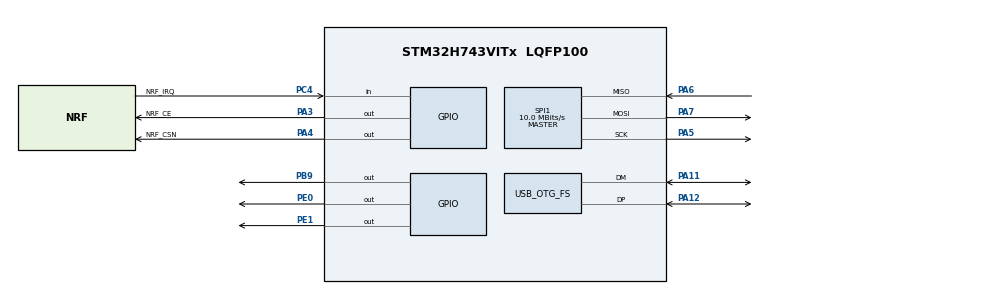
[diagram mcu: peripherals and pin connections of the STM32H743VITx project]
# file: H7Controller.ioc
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FREERTOS.Tasks01=defaultTask,24,128,StartDefaultTask,Default,NULL,Dynamic,NULL,NULL
FREERTOS.configENABLE_FPU=1
FREERTOS.configUSE_PREEMPTION=1
Mcu.Family=STM32H7
Mcu.Name=STM32H743VITx
Mcu.Package=LQFP100
NVIC.OTG_FS_IRQn=true\:5\:0\:false\:false\:true\:true\:false\:true\:true
NVIC.PriorityGroup=NVIC_PRIORITYGROUP_4
NVIC.TIM17_IRQn=true\:15\:0\:false\:false\:true\:false\:false\:true\:true
NVIC.TimeBase=TIM17_IRQn
NVIC.TimeBaseIP=TIM17
PA11.Mode=Device_Only
PA11.Signal=USB_OTG_FS_DM
PA12.Mode=Device_Only
PA12.Signal=USB_OTG_FS_DP
PA13\ (JTMS/SWDIO).Mode=Serial_Wire
PA13\ (JTMS/SWDIO).Signal=DEBUG_JTMS-SWDIO
PA14\ (JTCK/SWCLK).Mode=Serial_Wire
PA14\ (JTCK/SWCLK).Signal=DEBUG_JTCK-SWCLK
PA3.GPIO_Label=NRF_CE
PA3.GPIO_PuPd=GPIO_PULLDOWN
PA3.Signal=GPIO_Output
PA4.GPIO_Label=NRF_CSN
PA4.GPIO_PuPd=GPIO_PULLDOWN
PA4.Signal=GPIO_Output
PA5.Mode=Full_Duplex_Master
PA5.Signal=SPI1_SCK
PA6.Mode=Full_Duplex_Master
PA6.Signal=SPI1_MISO
PA7.Mode=Full_Duplex_Master
PA7.Signal=SPI1_MOSI
PB9.GPIO_PuPd=GPIO_PULLDOWN
PB9.Signal=GPIO_Output
PC4.GPIO_Label=NRF_IRQ
PC4.GPIO_PuPd=GPIO_PULLDOWN
PC4.Signal=GPIO_Input
PE0.GPIO_PuPd=GPIO_PULLDOWN
PE0.Signal=GPIO_Output
PE1.GPIO_PuPd=GPIO_PULLDOWN
PE1.Signal=GPIO_Output
PH0-OSC_IN\ (PH0).Mode=HSE-External-Clock-Source
PH0-OSC_IN\ (PH0).Signal=RCC_OSC_IN
ProjectManager.HeapSize=0x200
ProjectManager.StackSize=0x400
ProjectManager.TargetToolchain=Makefile
RCC.ADCFreq_Value=160000000
RCC.APB1Freq_Value=120000000
RCC.APB2Freq_Value=120000000
RCC.APB3Freq_Value=120000000
RCC.APB4Freq_Value=120000000
RCC.CortexFreq_Value=480000000
RCC.D1PPRE=RCC_APB3_DIV2
RCC.D2PPRE1=RCC_APB1_DIV2
RCC.D2PPRE2=RCC_APB2_DIV2
RCC.D3PPRE=RCC_APB4_DIV2
RCC.DIVM1=5
RCC.DIVM2=5
RCC.DIVM3=5
RCC.DIVN1=192
RCC.DIVN2=192
RCC.DIVN3=192
RCC.DIVP2=6
RCC.HCLKFreq_Value=240000000
RCC.HPRE=RCC_HCLK_DIV2
RCC.PLL2FRACN=0
RCC.PLL3FRACN=0
RCC.PLLFRACN=0
RCC.PLLSourceVirtual=RCC_PLLSOURCE_HSE
RCC.PWR_Regulator_Voltage_Scale=PWR_REGULATOR_VOLTAGE_SCALE0
RCC.ProductRev=revV
RCC.RCC_TIM_PRescaler_Selection=RCC_TIMPRES_DESACTIVATED
RCC.SPI123CLockSelection=RCC_SPI123CLKSOURCE_PLL2
RCC.SYSCLKFreq_VALUE=480000000
RCC.SYSCLKSource=RCC_SYSCLKSOURCE_PLLCLK
RCC.SupplySource=PWR_LDO_SUPPLY
RCC.USBCLockSelection=RCC_USBCLKSOURCE_HSI48
RCC.USBFreq_Value=48000000
SPI1.BaudRatePrescaler=SPI_BAUDRATEPRESCALER_16
SPI1.CalculateBaudRate=10.0 MBits/s
SPI1.DataSize=SPI_DATASIZE_8BIT
SPI1.Direction=SPI_DIRECTION_2LINES
SPI1.Mode=SPI_MODE_MASTER
SPI1.VirtualType=VM_MASTER
USB_DEVICE.APP_RX_DATA_SIZE-CDC_FS=1024
USB_DEVICE.APP_TX_DATA_SIZE-CDC_FS=1024
USB_DEVICE.CLASS_NAME_FS=CDC
USB_DEVICE.VirtualMode-CDC_FS=Cdc
USB_DEVICE.VirtualModeFS=Cdc_FS
USB_OTG_FS.VirtualMode=Device_Only
VP_FREERTOS_VS_CMSIS_V2.Mode=CMSIS_V2
VP_SYS_VS_tim17.Mode=TIM17
VP_USB_DEVICE_VS_USB_DEVICE_CDC_FS.Mode=CDC_FS
board=custom

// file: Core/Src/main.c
/* USER CODE BEGIN Header */
/**
  ******************************************************************************
  * @file           : main.c
  * @brief          : Main program body
  ******************************************************************************
  * @attention
  *
  * Copyright (c) 2023 STMicroelectronics.
  * All rights reserved.
  *
  * This software is licensed under terms that can be found in the LICENSE file
  * in the root directory of this software component.
  * If no LICENSE file comes with this software, it is provided AS-IS.
  *
  ******************************************************************************
  */
/* USER CODE END Header */
#include "main.h"
#include "cmsis_os.h"
#include "spi.h"
#include "usb_device.h"
#include "gpio.h"

/* USER CODE BEGIN Includes */
#include "nrf.h"
#include "Rtcc.h"
/* USER CODE END Includes */

void SystemClock_Config(void);
void MX_FREERTOS_Init(void);

int main(void)
{

  /* MCU Configuration--------------------------------------------------------*/

  /* Reset of all peripherals, Initializes the Flash interface and the Systick. */
  HAL_Init();

  /* Configure the system clock */
  SystemClock_Config();

  /* Initialize all configured peripherals */
  MX_GPIO_Init();
  MX_SPI1_Init();

  /* Init scheduler */
  osKernelInitialize();  /* Call init function for freertos objects (in freertos.c) */
  MX_FREERTOS_Init();

  /* Start scheduler */
  osKernelStart();
  /* We should never get here as control is now taken by the scheduler */
  /* Infinite loop */
  while (1)
  {

  }
}

void SystemClock_Config(void)
{
  RCC_OscInitTypeDef RCC_OscInitStruct = {0};
  RCC_ClkInitTypeDef RCC_ClkInitStruct = {0};

  /** Supply configuration update enable
  */
  HAL_PWREx_ConfigSupply(PWR_LDO_SUPPLY);

  /** Configure the main internal regulator output voltage
  */
  __HAL_PWR_VOLTAGESCALING_CONFIG(PWR_REGULATOR_VOLTAGE_SCALE1);

  while(!__HAL_PWR_GET_FLAG(PWR_FLAG_VOSRDY)) {}

  __HAL_RCC_SYSCFG_CLK_ENABLE();
  __HAL_PWR_VOLTAGESCALING_CONFIG(PWR_REGULATOR_VOLTAGE_SCALE0);

  while(!__HAL_PWR_GET_FLAG(PWR_FLAG_VOSRDY)) {}

  /** Initializes the RCC Oscillators according to the specified parameters
  * in the RCC_OscInitTypeDef structure.
  */
  RCC_OscInitStruct.OscillatorType = RCC_OSCILLATORTYPE_HSI48|RCC_OSCILLATORTYPE_HSE;
  RCC_OscInitStruct.HSEState = RCC_HSE_BYPASS;
  RCC_OscInitStruct.HSI48State = RCC_HSI48_ON;
  RCC_OscInitStruct.PLL.PLLState = RCC_PLL_ON;
  RCC_OscInitStruct.PLL.PLLSource = RCC_PLLSOURCE_HSE;
  RCC_OscInitStruct.PLL.PLLM = 5;
  RCC_OscInitStruct.PLL.PLLN = 192;
  RCC_OscInitStruct.PLL.PLLP = 2;
  RCC_OscInitStruct.PLL.PLLQ = 2;
  RCC_OscInitStruct.PLL.PLLR = 2;
  RCC_OscInitStruct.PLL.PLLRGE = RCC_PLL1VCIRANGE_2;
  RCC_OscInitStruct.PLL.PLLVCOSEL = RCC_PLL1VCOWIDE;
  RCC_OscInitStruct.PLL.PLLFRACN = 0;
  if (HAL_RCC_OscConfig(&RCC_OscInitStruct) != HAL_OK)
  {
    Error_Handler();
  }

  /** Initializes the CPU, AHB and APB buses clocks
  */
  RCC_ClkInitStruct.ClockType = RCC_CLOCKTYPE_HCLK|RCC_CLOCKTYPE_SYSCLK
                              |RCC_CLOCKTYPE_PCLK1|RCC_CLOCKTYPE_PCLK2
                              |RCC_CLOCKTYPE_D3PCLK1|RCC_CLOCKTYPE_D1PCLK1;
  RCC_ClkInitStruct.SYSCLKSource = RCC_SYSCLKSOURCE_PLLCLK;
  RCC_ClkInitStruct.SYSCLKDivider = RCC_SYSCLK_DIV1;
  RCC_ClkInitStruct.AHBCLKDivider = RCC_HCLK_DIV2;
  RCC_ClkInitStruct.APB3CLKDivider = RCC_APB3_DIV2;
  RCC_ClkInitStruct.APB1CLKDivider = RCC_APB1_DIV2;
  RCC_ClkInitStruct.APB2CLKDivider = RCC_APB2_DIV2;
  RCC_ClkInitStruct.APB4CLKDivider = RCC_APB4_DIV2;

  if (HAL_RCC_ClockConfig(&RCC_ClkInitStruct, FLASH_LATENCY_4) != HAL_OK)
  {
    Error_Handler();
  }
}

void HAL_TIM_PeriodElapsedCallback(TIM_HandleTypeDef *htim)
{
  if (htim->Instance == TIM17) {
    HAL_IncTick();
  }
}

void Error_Handler(void)
{
  __disable_irq();
  while (1)
  {
  }
}
